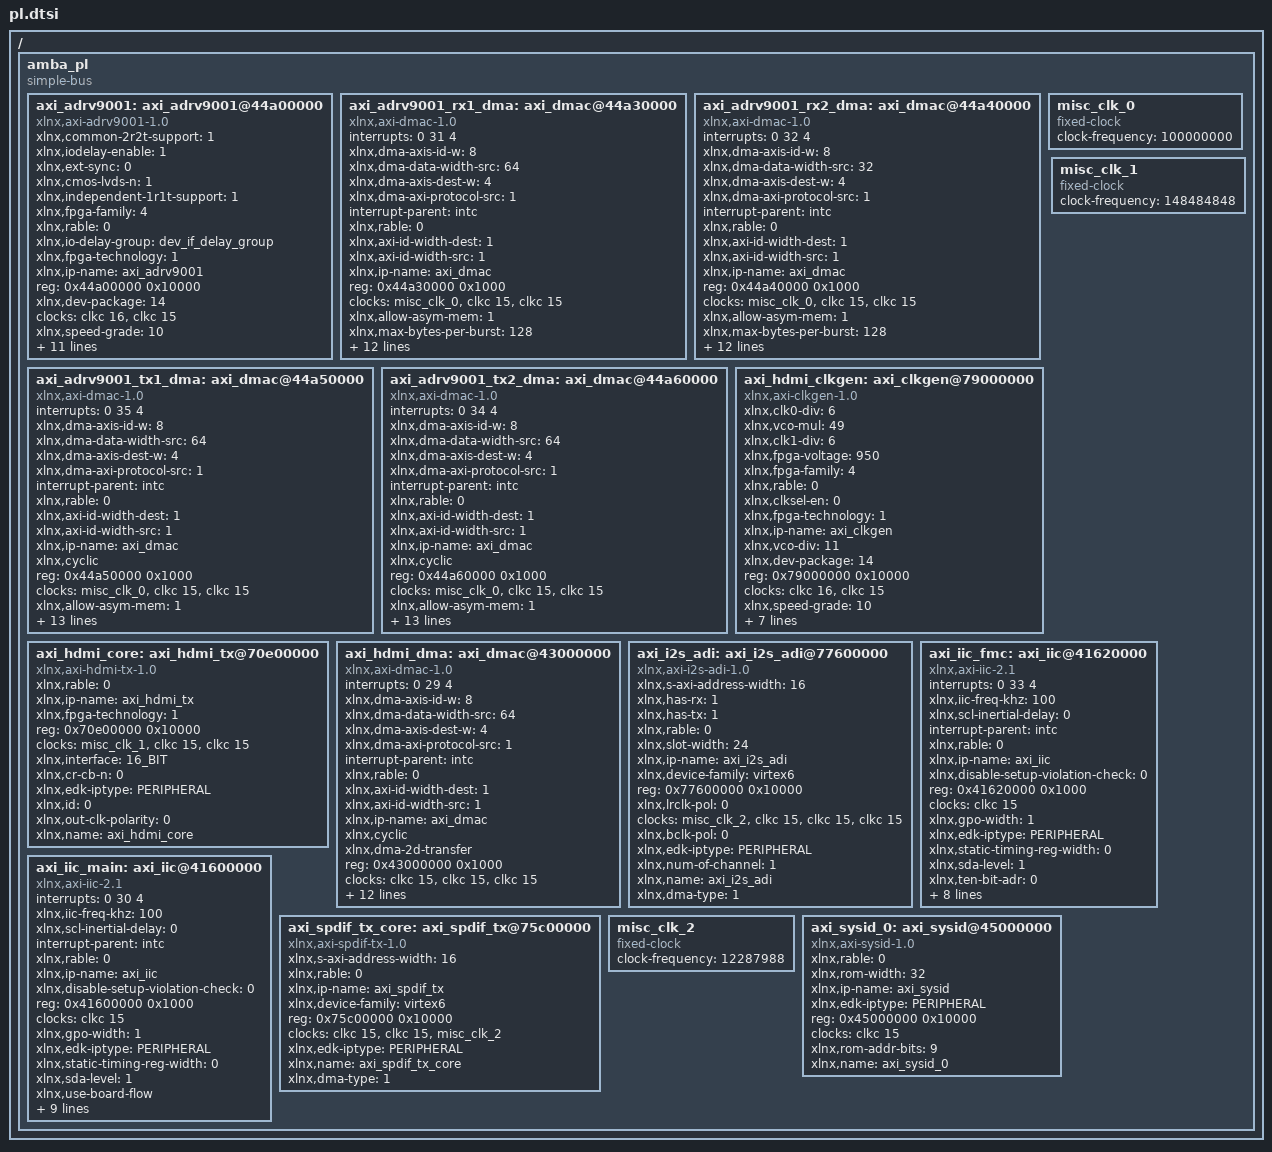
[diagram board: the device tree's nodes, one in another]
/ {
	amba_pl: amba_pl {
		ranges;
		compatible = "simple-bus";
		#address-cells = <1>;
		#size-cells = <1>;
		axi_adrv9001: axi_adrv9001@44a00000 {
			compatible = "xlnx,axi-adrv9001-1.0";
			xlnx,common-2r2t-support = <1>;
			xlnx,iodelay-enable = <1>;
			xlnx,ext-sync = <0>;
			xlnx,cmos-lvds-n = <1>;
			xlnx,independent-1r1t-support = <1>;
			xlnx,fpga-family = <4>;
			xlnx,rable = <0>;
			xlnx,io-delay-group = "dev_if_delay_group";
			xlnx,fpga-technology = <1>;
			xlnx,ip-name = "axi_adrv9001";
			reg = <0x44a00000 0x10000>;
			xlnx,dev-package = <14>;
			clocks = <&clkc 16>, <&clkc 15>;
			xlnx,speed-grade = <10>;
			xlnx,iodelay-ctrl = <1>;
			xlnx,disable-rx2-ssi = <0>;
			xlnx,disable-tx2-ssi = <0>;
			xlnx,dds-disable = <0>;
			xlnx,edk-iptype = "PERIPHERAL";
			xlnx,tdd-disable = <0>;
			xlnx,rx-use-bufg = <1>;
			xlnx,id = <0>;
			status = "okay";
			clock-names = "delay_clk" , "s_axi_aclk";
			xlnx,tx-use-bufg = <1>;
			xlnx,use-rx-clk-for-tx = <0>;
			xlnx,name = "axi_adrv9001";
		};
		axi_adrv9001_rx1_dma: axi_dmac@44a30000 {
			interrupts = < 0 31 4 >;
			xlnx,dma-axis-id-w = <8>;
			compatible = "xlnx,axi-dmac-1.0";
			xlnx,dma-data-width-src = <64>;
			xlnx,dma-axis-dest-w = <4>;
			xlnx,dma-axi-protocol-src = <1>;
			interrupt-parent = <&intc>;
			xlnx,rable = <0>;
			xlnx,axi-id-width-dest = <1>;
			xlnx,axi-id-width-src = <1>;
			xlnx,ip-name = "axi_dmac";
			reg = <0x44a30000 0x1000>;
			clocks = <&misc_clk_0>, <&clkc 15>, <&clkc 15>;
			xlnx,allow-asym-mem = <1>;
			xlnx,max-bytes-per-burst = <128>;
			xlnx,dma-data-width-dest = <64>;
			xlnx,fifo-size = <8>;
			xlnx,edk-iptype = "PERIPHERAL";
			xlnx,id = <0>;
			xlnx,dma-axi-protocol-dest = <1>;
			xlnx,dma-type-src = <2>;
			xlnx,dma-type-dest = <0>;
			xlnx,dma-length-width = <24>;
			status = "okay";
			xlnx,dma-axi-addr-width = <29>;
			clock-names = "fifo_wr_clk" , "m_dest_axi_aclk" , "s_axi_aclk";
			xlnx,async-clk-req-src;
			xlnx,async-clk-src-dest;
			interrupt-names = "irq";
			xlnx,name = "axi_adrv9001_rx1_dma";
		};
		axi_adrv9001_rx2_dma: axi_dmac@44a40000 {
			interrupts = < 0 32 4 >;
			xlnx,dma-axis-id-w = <8>;
			compatible = "xlnx,axi-dmac-1.0";
			xlnx,dma-data-width-src = <32>;
			xlnx,dma-axis-dest-w = <4>;
			xlnx,dma-axi-protocol-src = <1>;
			interrupt-parent = <&intc>;
			xlnx,rable = <0>;
			xlnx,axi-id-width-dest = <1>;
			xlnx,axi-id-width-src = <1>;
			xlnx,ip-name = "axi_dmac";
			reg = <0x44a40000 0x1000>;
			clocks = <&misc_clk_0>, <&clkc 15>, <&clkc 15>;
			xlnx,allow-asym-mem = <1>;
			xlnx,max-bytes-per-burst = <128>;
			xlnx,dma-data-width-dest = <64>;
			xlnx,fifo-size = <8>;
			xlnx,edk-iptype = "PERIPHERAL";
			xlnx,id = <0>;
			xlnx,dma-axi-protocol-dest = <1>;
			xlnx,dma-type-src = <2>;
			xlnx,dma-type-dest = <0>;
			xlnx,dma-length-width = <24>;
			status = "okay";
			xlnx,dma-axi-addr-width = <29>;
			clock-names = "fifo_wr_clk" , "m_dest_axi_aclk" , "s_axi_aclk";
			xlnx,async-clk-req-src;
			xlnx,async-clk-src-dest;
			interrupt-names = "irq";
			xlnx,name = "axi_adrv9001_rx2_dma";
		};
		axi_adrv9001_tx1_dma: axi_dmac@44a50000 {
			interrupts = < 0 35 4 >;
			xlnx,dma-axis-id-w = <8>;
			compatible = "xlnx,axi-dmac-1.0";
			xlnx,dma-data-width-src = <64>;
			xlnx,dma-axis-dest-w = <4>;
			xlnx,dma-axi-protocol-src = <1>;
			interrupt-parent = <&intc>;
			xlnx,rable = <0>;
			xlnx,axi-id-width-dest = <1>;
			xlnx,axi-id-width-src = <1>;
			xlnx,ip-name = "axi_dmac";
			xlnx,cyclic;
			reg = <0x44a50000 0x1000>;
			clocks = <&misc_clk_0>, <&clkc 15>, <&clkc 15>;
			xlnx,allow-asym-mem = <1>;
			xlnx,max-bytes-per-burst = <128>;
			xlnx,dma-data-width-dest = <64>;
			xlnx,fifo-size = <8>;
			xlnx,edk-iptype = "PERIPHERAL";
			xlnx,id = <0>;
			xlnx,dma-axi-protocol-dest = <1>;
			xlnx,dma-type-src = <0>;
			xlnx,dma-type-dest = <1>;
			xlnx,dma-length-width = <24>;
			status = "okay";
			xlnx,dma-axi-addr-width = <29>;
			clock-names = "m_axis_aclk" , "m_src_axi_aclk" , "s_axi_aclk";
			xlnx,async-clk-dest-req;
			xlnx,async-clk-src-dest;
			interrupt-names = "irq";
			xlnx,name = "axi_adrv9001_tx1_dma";
		};
		axi_adrv9001_tx2_dma: axi_dmac@44a60000 {
			interrupts = < 0 34 4 >;
			xlnx,dma-axis-id-w = <8>;
			compatible = "xlnx,axi-dmac-1.0";
			xlnx,dma-data-width-src = <64>;
			xlnx,dma-axis-dest-w = <4>;
			xlnx,dma-axi-protocol-src = <1>;
			interrupt-parent = <&intc>;
			xlnx,rable = <0>;
			xlnx,axi-id-width-dest = <1>;
			xlnx,axi-id-width-src = <1>;
			xlnx,ip-name = "axi_dmac";
			xlnx,cyclic;
			reg = <0x44a60000 0x1000>;
			clocks = <&misc_clk_0>, <&clkc 15>, <&clkc 15>;
			xlnx,allow-asym-mem = <1>;
			xlnx,max-bytes-per-burst = <128>;
			xlnx,dma-data-width-dest = <32>;
			xlnx,fifo-size = <8>;
			xlnx,edk-iptype = "PERIPHERAL";
			xlnx,id = <0>;
			xlnx,dma-axi-protocol-dest = <1>;
			xlnx,dma-type-src = <0>;
			xlnx,dma-type-dest = <1>;
			xlnx,dma-length-width = <24>;
			status = "okay";
			xlnx,dma-axi-addr-width = <29>;
			clock-names = "m_axis_aclk" , "m_src_axi_aclk" , "s_axi_aclk";
			xlnx,async-clk-dest-req;
			xlnx,async-clk-src-dest;
			interrupt-names = "irq";
			xlnx,name = "axi_adrv9001_tx2_dma";
		};
		misc_clk_0: misc_clk_0 {
			compatible = "fixed-clock";
			clock-frequency = <100000000>;
			#clock-cells = <0>;
		};
		axi_hdmi_clkgen: axi_clkgen@79000000 {
			compatible = "xlnx,axi-clkgen-1.0";
			xlnx,clk0-div = <6>;
			xlnx,vco-mul = <49>;
			xlnx,clk1-div = <6>;
			xlnx,fpga-voltage = <950>;
			xlnx,fpga-family = <4>;
			xlnx,rable = <0>;
			xlnx,clksel-en = <0>;
			xlnx,fpga-technology = <1>;
			xlnx,ip-name = "axi_clkgen";
			xlnx,vco-div = <11>;
			xlnx,dev-package = <14>;
			reg = <0x79000000 0x10000>;
			clocks = <&clkc 16>, <&clkc 15>;
			xlnx,speed-grade = <10>;
			xlnx,clkin2-period = <5>;
			xlnx,edk-iptype = "PERIPHERAL";
			xlnx,id = <0>;
			status = "okay";
			clock-names = "clk" , "s_axi_aclk";
			xlnx,clk0-phase = <0>;
			xlnx,name = "axi_hdmi_clkgen";
			xlnx,clk1-phase = <0>;
			xlnx,clkin-period = <5>;
		};
		axi_hdmi_core: axi_hdmi_tx@70e00000 {
			compatible = "xlnx,axi-hdmi-tx-1.0";
			xlnx,rable = <0>;
			xlnx,ip-name = "axi_hdmi_tx";
			xlnx,fpga-technology = <1>;
			reg = <0x70e00000 0x10000>;
			clocks = <&misc_clk_1>, <&clkc 15>, <&clkc 15>;
			xlnx,interface = "16_BIT";
			xlnx,cr-cb-n = <0>;
			xlnx,edk-iptype = "PERIPHERAL";
			xlnx,id = <0>;
			status = "okay";
			clock-names = "reference_clk" , "s_axi_aclk" , "vdma_clk";
			xlnx,out-clk-polarity = <0>;
			xlnx,name = "axi_hdmi_core";
		};
		misc_clk_1: misc_clk_1 {
			compatible = "fixed-clock";
			clock-frequency = <148484848>;
			#clock-cells = <0>;
		};
		axi_hdmi_dma: axi_dmac@43000000 {
			interrupts = < 0 29 4 >;
			xlnx,dma-axis-id-w = <8>;
			compatible = "xlnx,axi-dmac-1.0";
			xlnx,dma-data-width-src = <64>;
			xlnx,dma-axis-dest-w = <4>;
			xlnx,dma-axi-protocol-src = <1>;
			interrupt-parent = <&intc>;
			xlnx,rable = <0>;
			xlnx,axi-id-width-dest = <1>;
			xlnx,axi-id-width-src = <1>;
			xlnx,ip-name = "axi_dmac";
			xlnx,cyclic;
			xlnx,dma-2d-transfer;
			reg = <0x43000000 0x1000>;
			clocks = <&clkc 15>, <&clkc 15>, <&clkc 15>;
			xlnx,allow-asym-mem = <1>;
			xlnx,max-bytes-per-burst = <128>;
			xlnx,dma-data-width-dest = <64>;
			xlnx,fifo-size = <8>;
			xlnx,edk-iptype = "PERIPHERAL";
			xlnx,id = <0>;
			xlnx,dma-axi-protocol-dest = <1>;
			xlnx,dma-type-src = <0>;
			xlnx,dma-type-dest = <1>;
			xlnx,dma-length-width = <24>;
			status = "okay";
			xlnx,dma-axi-addr-width = <29>;
			clock-names = "m_axis_aclk" , "m_src_axi_aclk" , "s_axi_aclk";
			interrupt-names = "irq";
			xlnx,name = "axi_hdmi_dma";
		};
		axi_i2s_adi: axi_i2s_adi@77600000 {
			xlnx,s-axi-address-width = <16>;
			compatible = "xlnx,axi-i2s-adi-1.0";
			xlnx,has-rx = <1>;
			xlnx,has-tx = <1>;
			xlnx,rable = <0>;
			xlnx,slot-width = <24>;
			xlnx,ip-name = "axi_i2s_adi";
			xlnx,device-family = "virtex6";
			reg = <0x77600000 0x10000>;
			xlnx,lrclk-pol = <0>;
			clocks = <&misc_clk_2>, <&clkc 15>, <&clkc 15>, <&clkc 15>;
			xlnx,bclk-pol = <0>;
			xlnx,edk-iptype = "PERIPHERAL";
			status = "okay";
			clock-names = "data_clk_i" , "dma_req_rx_aclk" , "dma_req_tx_aclk" , "s_axi_aclk";
			xlnx,num-of-channel = <1>;
			xlnx,name = "axi_i2s_adi";
			xlnx,dma-type = <1>;
		};
		axi_iic_fmc: axi_iic@41620000 {
			interrupts = < 0 33 4 >;
			xlnx,iic-freq-khz = <100>;
			compatible = "xlnx,axi-iic-2.1" , "xlnx,xps-iic-2.00.a";
			xlnx,scl-inertial-delay = <0>;
			interrupt-parent = <&intc>;
			xlnx,rable = <0>;
			xlnx,ip-name = "axi_iic";
			xlnx,disable-setup-violation-check = <0>;
			reg = <0x41620000 0x1000>;
			clocks = <&clkc 15>;
			xlnx,gpo-width = <1>;
			xlnx,edk-iptype = "PERIPHERAL";
			xlnx,static-timing-reg-width = <0>;
			xlnx,sda-level = <1>;
			status = "okay";
			clock-names = "s_axi_aclk";
			xlnx,ten-bit-adr = <0>;
			xlnx,default-value = <0x00>;
			interrupt-names = "iic2intc_irpt";
			xlnx,timing-reg-width = <32>;
			xlnx,iic-board-interface = "Custom";
			xlnx,iic-freq = <100000>;
			xlnx,smbus-pmbus-host = <0>;
			xlnx,sda-inertial-delay = <0>;
			xlnx,name = "axi_iic_fmc";
			xlnx,axi-aclk-freq-mhz = <100>;
		};
		axi_iic_main: axi_iic@41600000 {
			interrupts = < 0 30 4 >;
			xlnx,iic-freq-khz = <100>;
			compatible = "xlnx,axi-iic-2.1" , "xlnx,xps-iic-2.00.a";
			xlnx,scl-inertial-delay = <0>;
			interrupt-parent = <&intc>;
			xlnx,rable = <0>;
			xlnx,ip-name = "axi_iic";
			xlnx,disable-setup-violation-check = <0>;
			reg = <0x41600000 0x1000>;
			clocks = <&clkc 15>;
			xlnx,gpo-width = <1>;
			xlnx,edk-iptype = "PERIPHERAL";
			xlnx,static-timing-reg-width = <0>;
			xlnx,sda-level = <1>;
			status = "okay";
			clock-names = "s_axi_aclk";
			xlnx,use-board-flow;
			xlnx,ten-bit-adr = <0>;
			xlnx,default-value = <0x00>;
			interrupt-names = "iic2intc_irpt";
			xlnx,timing-reg-width = <32>;
			xlnx,iic-board-interface = "Custom";
			xlnx,iic-freq = <100000>;
			xlnx,smbus-pmbus-host = <0>;
			xlnx,sda-inertial-delay = <0>;
			xlnx,name = "axi_iic_main";
			xlnx,axi-aclk-freq-mhz = <100>;
		};
		axi_spdif_tx_core: axi_spdif_tx@75c00000 {
			compatible = "xlnx,axi-spdif-tx-1.0";
			xlnx,s-axi-address-width = <16>;
			xlnx,rable = <0>;
			xlnx,ip-name = "axi_spdif_tx";
			xlnx,device-family = "virtex6";
			reg = <0x75c00000 0x10000>;
			clocks = <&clkc 15>, <&clkc 15>, <&misc_clk_2>;
			xlnx,edk-iptype = "PERIPHERAL";
			status = "okay";
			clock-names = "dma_req_aclk" , "s_axi_aclk" , "spdif_data_clk";
			xlnx,name = "axi_spdif_tx_core";
			xlnx,dma-type = <1>;
		};
		misc_clk_2: misc_clk_2 {
			compatible = "fixed-clock";
			clock-frequency = <12287988>;
			#clock-cells = <0>;
		};
		axi_sysid_0: axi_sysid@45000000 {
			xlnx,rable = <0>;
			compatible = "xlnx,axi-sysid-1.0";
			status = "okay";
			clock-names = "s_axi_aclk";
			xlnx,rom-width = <32>;
			xlnx,ip-name = "axi_sysid";
			xlnx,edk-iptype = "PERIPHERAL";
			reg = <0x45000000 0x10000>;
			clocks = <&clkc 15>;
			xlnx,rom-addr-bits = <9>;
			xlnx,name = "axi_sysid_0";
		};
	};
};
